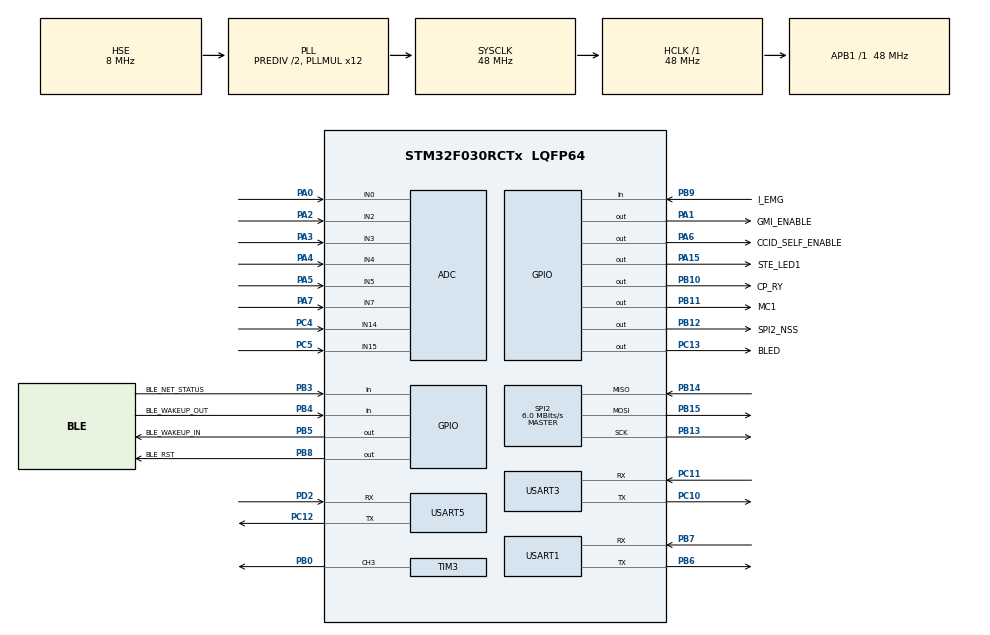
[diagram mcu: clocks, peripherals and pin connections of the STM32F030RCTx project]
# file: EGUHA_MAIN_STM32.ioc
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Mcu.Family=STM32F0
Dma.TIM7_UP.1.PeriphInc=DMA_PINC_DISABLE
Dma.TIM7_UP.1.Mode=DMA_CIRCULAR
Dma.ADC.0.Mode=DMA_CIRCULAR
SPI2.VirtualType=VM_MASTER
PC15OSC32_OUT.Signal=GPIO_Output
PC10.Signal=USART3_TX
PC12.Signal=USART5_TX
VP_IWDG_VS_IWDG.Mode=IWDG_Activate
Dma.ADC.0.Priority=DMA_PRIORITY_HIGH
VP_TIM3_VS_no_output2.Mode=Output Compare2 No Output
PA6.GPIO_Label=CCID_SELF_ENABLE
PC5.Mode=IN15
PC13.GPIO_Label=BLED
PB11.Signal=GPIO_Output
PB13.Signal=SPI2_SCK
PB15.Signal=SPI2_MOSI
RCC.SYSCLKSource=RCC_SYSCLKSOURCE_PLLCLK
ProjectManager.StackSize=0x400
USART3.VirtualMode-Asynchronous=VM_ASYNC
VP_TIM7_VS_ClockSourceINT.Mode=Enable_Timer
PA15.GPIO_Label=STE_LED1
NVIC.ADC1_IRQn=true\:0\:0\:false\:false\:true\:true\:true
PA4.Mode=IN4
Dma.ADC.0.PeriphInc=DMA_PINC_DISABLE
RCC.HCLKFreq_Value=48000000
TIM3.Period=23999
PB6.Signal=USART1_TX
PB6.Mode=Asynchronous
TIM3.Pulse-Output\ Compare1\ No\ Output=1200
TIM7.Period=799
RCC.AHBFreq_Value=48000000
SPI2.BaudRatePrescaler=SPI_BAUDRATEPRESCALER_8
USART5.VirtualMode-Asynchronous=VM_ASYNC
Dma.ADC.0.Direction=DMA_PERIPH_TO_MEMORY
PC15OSC32_OUT.GPIO_Label=RLED
ADC.SamplingTime=ADC_SAMPLETIME_28CYCLES_5
VP_TIM3_VS_no_output4.Mode=Output Compare4 No Output
TIM3.Pulse-PWM\ Generation3\ CH3=23999
Dma.TIM7_UP.1.Priority=DMA_PRIORITY_LOW
RCC.PLLMUL=RCC_PLL_MUL12
PB12.GPIO_Label=SPI2_NSS
PA14.Mode=Serial_Wire
PB14.Mode=Full_Duplex_Master
TIM3.Prescaler=1
PA0.Mode=IN0
SPI2.CalculateBaudRate=6.0 MBits/s
TIM3.Channel-Output\ Compare4\ No\ Output=TIM_CHANNEL_4
PB7.Signal=USART1_RX
TIM6.Period=2399
PA0.Signal=ADC_IN0
Dma.ADC.0.MemInc=DMA_MINC_ENABLE
Mcu.Package=LQFP64
PB9.Signal=GPIO_Input
PA6.Signal=GPIO_Output
SPI2.Mode=SPI_MODE_MASTER
Dma.ADC.0.Instance=DMA1_Channel1
PA15.Signal=GPIO_Output
PC11.Mode=Asynchronous
Dma.ADC.0.MemDataAlignment=DMA_MDATAALIGN_HALFWORD
PB5.GPIO_Label=BLE_WAKEUP_IN
Dma.Request1=TIM7_UP
RCC.APB1TimFreq_Value=48000000
SPI2.Direction=SPI_DIRECTION_2LINES
PC5.Signal=ADC_IN15
PB13.Mode=Full_Duplex_Master
NVIC.USART1_IRQn=true\:0\:0\:false\:false\:true\:true\:true
PF1-OSC_OUT.Mode=HSE-External-Oscillator
Dma.Request0=ADC
PF1-OSC_OUT.Signal=RCC_OSC_OUT
PC14OSC32_IN.Signal=GPIO_Output
PC4.Mode=IN14
PB4.Signal=GPIO_Input
PA3.Signal=ADC_IN3
PA5.Mode=IN5
PB3.GPIO_Label=BLE_NET_STATUS
RCC.PLLSourceVirtual=RCC_PLLSOURCE_HSE
PA7.Mode=IN7
TIM3.Channel-Output\ Compare1\ No\ Output=TIM_CHANNEL_1
PB9.GPIO_Label=I_EMG
PC11.Signal=USART3_RX
PC13.Signal=GPIO_Output
TIM6.Prescaler=1
PC4.Signal=ADC_IN14
PC10.Mode=Asynchronous
VP_TIM6_VS_ClockSourceINT.Mode=Enable_Timer
PB11.GPIO_Label=MC1
SH.S_TIM3_CH3.0=TIM3_CH3,PWM Generation3 CH3
Dma.TIM7_UP.1.PeriphDataAlignment=DMA_PDATAALIGN_WORD
Dma.ADC.0.PeriphDataAlignment=DMA_PDATAALIGN_HALFWORD
NVIC.TIM6_IRQn=true\:0\:0\:false\:false\:true\:true\:true
USART1.VirtualMode-Asynchronous=VM_ASYNC
PA3.Mode=IN3
PA13.Signal=SYS_SWDIO
TIM3.Channel-PWM\ Generation3\ CH3=TIM_CHANNEL_3
PB8.GPIO_Label=BLE_RST
ProjectManager.TargetToolchain=STM32CubeIDE
Dma.TIM7_UP.1.MemInc=DMA_MINC_ENABLE
PB10.GPIO_Label=CP_RY
TIM3.Pulse-Output\ Compare4\ No\ Output=12000
Dma.TIM7_UP.1.MemDataAlignment=DMA_MDATAALIGN_WORD
RCC.PLLDivider=RCC_PREDIV_DIV2
PA1.Signal=GPIO_Output
PF0-OSC_IN.Mode=HSE-External-Oscillator
PB10.Signal=GPIO_Output
Dma.TIM7_UP.1.Direction=DMA_MEMORY_TO_PERIPH
PB14.Signal=SPI2_MISO
PD2.Mode=Asynchronous
PA5.Signal=ADC_IN5
ADC.DMAContinuousRequests=ENABLE
PC12.Mode=Asynchronous
TIM7.Prescaler=1
board=custom
VP_TIM3_VS_no_output1.Mode=Output Compare1 No Output
PB15.Mode=Full_Duplex_Master
NVIC.TIM3_IRQn=true\:0\:0\:false\:false\:true\:true\:true
PB4.GPIO_Label=BLE_WAKEUP_OUT
TIM3.Pulse-Output\ Compare2\ No\ Output=22800
PA1.GPIO_Label=GMI_ENABLE
NVIC.USART3_6_IRQn=true\:0\:0\:false\:false\:true\:true\:true
PA13.Mode=Serial_Wire
Mcu.Name=STM32F030RCTx
PA2.Signal=ADC_IN2
PB3.Signal=GPIO_Input
PA4.Signal=ADC_IN4
RCC.SYSCLKFreq_VALUE=48000000
PB5.Signal=GPIO_Output
Dma.TIM7_UP.1.Instance=DMA1_Channel4
TIM3.Channel-Output\ Compare2\ No\ Output=TIM_CHANNEL_2
PB7.Mode=Asynchronous
PA14.Signal=SYS_SWCLK
ProjectManager.HeapSize=0x200
IWDG.Prescaler=IWDG_PRESCALER_256
PA2.Mode=IN2
PB8.Signal=GPIO_Output
PF0-OSC_IN.Signal=RCC_OSC_IN
PD2.Signal=USART5_RX
RCC.APB1Freq_Value=48000000
PB0.Signal=S_TIM3_CH3
ADC.ContinuousConvMode=ENABLE
PC14OSC32_IN.GPIO_Label=GLED
PB12.Signal=GPIO_Output
PA7.Signal=ADC_IN7

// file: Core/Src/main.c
/* USER CODE BEGIN Header */
/**
  ******************************************************************************
  * @file           : main.c
  * @brief          : Main program body
  ******************************************************************************
  * @attention
  *
  * <h2><center>&copy; Copyright (c) 2025 STMicroelectronics.
  * All rights reserved.</center></h2>
  *
  * This software component is licensed by ST under BSD 3-Clause license,
  * the "License"; You may not use this file except in compliance with the
  * License. You may obtain a copy of the License at:
  *                        opensource.org/licenses/BSD-3-Clause
  *
  ******************************************************************************
  */
/* USER CODE END Header */
#include "main.h"
#include "adc.h"
#include "dma.h"
#include "iwdg.h"
#include "spi.h"
#include "tim.h"
#include "usart.h"
#include "gpio.h"

/* USER CODE BEGIN Includes */
#include "egtn_jumptoapp.h"
#include "egtn_app_nonos_loop.h"
/* USER CODE END Includes */

void SystemClock_Config(void);

int main(void)
{
  /* USER CODE BEGIN 1 */
	EGTN_JUMPTOAPP_relocate_vector_table_to_ram();
	__enable_irq();

  /* USER CODE END 1 */

  /* MCU Configuration--------------------------------------------------------*/

  /* Reset of all peripherals, Initializes the Flash interface and the Systick. */
  HAL_Init();

  /* Configure the system clock */
  SystemClock_Config();

  /* Initialize all configured peripherals */
  MX_GPIO_Init();
  MX_DMA_Init();
  MX_ADC_Init();
  MX_IWDG_Init();
  MX_TIM3_Init();
  MX_TIM6_Init();
  MX_USART1_UART_Init();
  MX_USART3_UART_Init();
  MX_USART5_UART_Init();
  MX_SPI2_Init();
  MX_TIM7_Init();

  /* Infinite loop */
  /* USER CODE BEGIN WHILE */
  while (1)
  {
	  EGUHAsystem();
    /* USER CODE END WHILE */

  }
}

void SystemClock_Config(void)
{
  RCC_OscInitTypeDef RCC_OscInitStruct = {0};
  RCC_ClkInitTypeDef RCC_ClkInitStruct = {0};
  RCC_PeriphCLKInitTypeDef PeriphClkInit = {0};

  /** Initializes the RCC Oscillators according to the specified parameters
  * in the RCC_OscInitTypeDef structure.
  */
  RCC_OscInitStruct.OscillatorType = RCC_OSCILLATORTYPE_HSI14|RCC_OSCILLATORTYPE_LSI
                              |RCC_OSCILLATORTYPE_HSE;
  RCC_OscInitStruct.HSEState = RCC_HSE_ON;
  RCC_OscInitStruct.HSI14State = RCC_HSI14_ON;
  RCC_OscInitStruct.HSI14CalibrationValue = 16;
  RCC_OscInitStruct.LSIState = RCC_LSI_ON;
  RCC_OscInitStruct.PLL.PLLState = RCC_PLL_ON;
  RCC_OscInitStruct.PLL.PLLSource = RCC_PLLSOURCE_HSE;
  RCC_OscInitStruct.PLL.PLLMUL = RCC_PLL_MUL12;
  RCC_OscInitStruct.PLL.PREDIV = RCC_PREDIV_DIV2;
  if (HAL_RCC_OscConfig(&RCC_OscInitStruct) != HAL_OK)
  {
    Error_Handler();
  }
  /** Initializes the CPU, AHB and APB buses clocks
  */
  RCC_ClkInitStruct.ClockType = RCC_CLOCKTYPE_HCLK|RCC_CLOCKTYPE_SYSCLK
                              |RCC_CLOCKTYPE_PCLK1;
  RCC_ClkInitStruct.SYSCLKSource = RCC_SYSCLKSOURCE_PLLCLK;
  RCC_ClkInitStruct.AHBCLKDivider = RCC_SYSCLK_DIV1;
  RCC_ClkInitStruct.APB1CLKDivider = RCC_HCLK_DIV1;

  if (HAL_RCC_ClockConfig(&RCC_ClkInitStruct, FLASH_LATENCY_1) != HAL_OK)
  {
    Error_Handler();
  }
  PeriphClkInit.PeriphClockSelection = RCC_PERIPHCLK_USART1;
  PeriphClkInit.Usart1ClockSelection = RCC_USART1CLKSOURCE_PCLK1;
  if (HAL_RCCEx_PeriphCLKConfig(&PeriphClkInit) != HAL_OK)
  {
    Error_Handler();
  }
}

void Error_Handler(void)
{
  __disable_irq();
  while (1)
  {
  }
}

/************************ (C) COPYRIGHT STMicroelectronics *****END OF FILE****/
